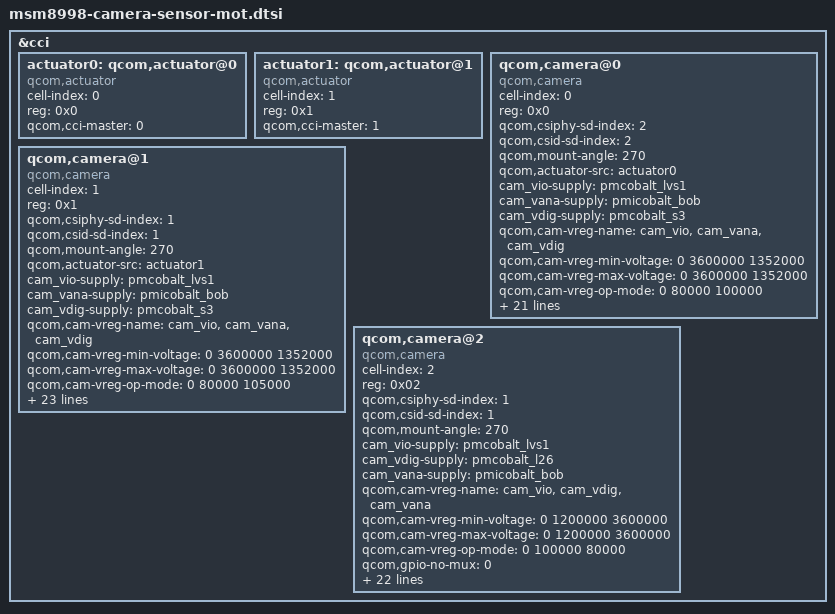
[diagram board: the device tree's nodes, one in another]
/*
 * Copyright (c) 2016, The Linux Foundation. All rights reserved.
 *
 * This program is free software; you can redistribute it and/or modify
 * it under the terms of the GNU General Public License version 2 and
 * only version 2 as published by the Free Software Foundation.
 *
 * This program is distributed in the hope that it will be useful,
 * but WITHOUT ANY WARRANTY; without even the implied warranty of
 * MERCHANTABILITY or FITNESS FOR A PARTICULAR PURPOSE.  See the
 * GNU General Public License for more details.
 */

&cci {
	/* IMX386 RGB Actuator */
	actuator0: qcom,actuator@0 {
		cell-index = <0>;
		reg = <0x0>;
		compatible = "qcom,actuator";
		qcom,cci-master = <0>;
	};

	/* IMX386 MONO Actuator */
	actuator1: qcom,actuator@1 {
		cell-index = <1>;
		reg = <0x1>;
		compatible = "qcom,actuator";
		qcom,cci-master = <1>;
	};

	/* IMX386 RGB & IMX258*/
	qcom,camera@0 {
		cell-index = <0>;
		compatible = "qcom,camera";
		reg = <0x0>;
		qcom,csiphy-sd-index = <2>;
		qcom,csid-sd-index = <2>;
		qcom,mount-angle = <270>;
		qcom,actuator-src = <&actuator0>;
		cam_vio-supply = <&pmcobalt_lvs1>;
		cam_vana-supply = <&pmicobalt_bob>;
		cam_vdig-supply = <&pmcobalt_s3>;
		qcom,cam-vreg-name = "cam_vio", "cam_vana", "cam_vdig";
		qcom,cam-vreg-min-voltage = <0 3600000 1352000>;
		qcom,cam-vreg-max-voltage = <0 3600000 1352000>;
		qcom,cam-vreg-op-mode = <0 80000 100000>;
		qcom,gpio-no-mux = <0>;
		pinctrl-names = "cam_default", "cam_suspend";
		pinctrl-0 = <&cam_sensor_mclk2_active
				 &cam_sensor_rear_active>;
		pinctrl-1 = <&cam_sensor_mclk2_suspend
				 &cam_sensor_rear_suspend>;
		gpios = <&tlmm 15 0>,
			<&tlmm 23 0>,
			<&tlmm 24 0>,
			<&tlmm 22 0>,
			<&tlmm 104 0>;
		qcom,gpio-reset = <1>;
		qcom,gpio-vdig = <2>;
		qcom,gpio-vana = <3>;
		/* gpio-standby: IMX386 toggle line between mono and rgb */
		qcom,gpio-standby = <4>;
		qcom,gpio-req-tbl-num = <0 1 2 3 4>;
		qcom,gpio-req-tbl-flags = <1 0 0 0 0>;
		qcom,gpio-req-tbl-label = "CAMIF_MCLK2",
					"CAM_RESET0",
					"CAM_VDIG",
					"CAM_VANA",
					"CAM_STANDBY";
		qcom,sensor-position = <1>;
		qcom,sensor-mode = <0>;
		qcom,cci-master = <0>;
		status = "ok";
		clocks = <&clock_mmss clk_mclk2_clk_src>,
				<&clock_mmss clk_mmss_camss_mclk2_clk>;
		clock-names = "cam_src_clk", "cam_clk";
		qcom,clock-rates = <24000000 0>;
	};

	/* IMX386 MONO and IMX258 MONO */
	qcom,camera@1 {
		cell-index = <1>;
		compatible = "qcom,camera";
		reg = <0x1>;
		qcom,csiphy-sd-index = <1>;
		qcom,csid-sd-index = <1>;
		qcom,mount-angle = <270>;
		qcom,actuator-src = <&actuator1>;
		cam_vio-supply = <&pmcobalt_lvs1>;
		cam_vana-supply = <&pmicobalt_bob>;
		cam_vdig-supply = <&pmcobalt_s3>;
		qcom,cam-vreg-name = "cam_vio", "cam_vana", "cam_vdig";
		qcom,cam-vreg-min-voltage = <0 3600000 1352000>;
		qcom,cam-vreg-max-voltage = <0 3600000 1352000>;
		qcom,cam-vreg-op-mode = <0 80000 105000>;
		qcom,gpio-no-mux = <0>;
		pinctrl-names = "cam_default", "cam_suspend";
		pinctrl-0 = <&cam_sensor_mclk2_active
				 &cam_sensor_rear_active>;
		pinctrl-1 = <&cam_sensor_mclk2_suspend
				 &cam_sensor_rear_suspend>;
		gpios = <&tlmm 15 0>,
			<&tlmm 23 0>,
			<&tlmm 24 0>,
			<&tlmm 22 0>,
			<&tlmm 128 0>,
			<&tlmm 104 0>;
		qcom,gpio-reset = <1>;
		qcom,gpio-vdig = <2>;
		qcom,gpio-vana = <3>;
		qcom,gpio-standby = <4>;
		/* gpio-custom1: IMX386 toggle line between mono and rgb */
		qcom,gpio-custom1 = <5>;
		qcom,gpio-req-tbl-num = <0 1 2 3 4 5>;
		qcom,gpio-req-tbl-flags = <1 0 0 0 0 0>;
		qcom,gpio-req-tbl-label = "CAMIF_MCLK2",
					"CAM_RESET0",
					"CAM_VDIG",
					"CAM_VANA",
					"CAM_STANDBY",
					"CAM_CUSTOM1";
		qcom,sensor-position = <1>;
		qcom,sensor-mode = <0>;
		qcom,cci-master = <1>;
		status = "ok";
		clocks = <&clock_mmss clk_mclk2_clk_src>,
				<&clock_mmss clk_mmss_camss_mclk2_clk>;
		clock-names = "cam_src_clk", "cam_clk";
		qcom,clock-rates = <24000000 0>;
	};

	/* OV5693 & OV5695 */
	qcom,camera@2 {
		cell-index = <2>;
		compatible = "qcom,camera";
		reg = <0x02>;
		qcom,csiphy-sd-index = <1>;
		qcom,csid-sd-index = <1>;
		qcom,mount-angle = <270>;
		cam_vio-supply = <&pmcobalt_lvs1>;
		cam_vdig-supply = <&pmcobalt_l26>;
		cam_vana-supply = <&pmicobalt_bob>;
		qcom,cam-vreg-name = "cam_vio", "cam_vdig", "cam_vana";
		qcom,cam-vreg-min-voltage = <0 1200000 3600000>;
		qcom,cam-vreg-max-voltage = <0 1200000 3600000>;
		qcom,cam-vreg-op-mode = <0 100000 80000>;
		qcom,gpio-no-mux = <0>;
		pinctrl-names = "cam_default", "cam_suspend";
		pinctrl-0 = <&cam_sensor_mclk1_active
			&cam_sensor_front_active>;
		pinctrl-1 = <&cam_sensor_mclk1_suspend
			&cam_sensor_front_suspend>;
		gpios = <&tlmm 14 0>,
			<&tlmm 16 0>,
			<&tlmm 104 0>,
			<&tlmm 128 0>,
			<&tlmm 24 0>,
			<&tlmm 22 0>;
		qcom,gpio-reset = <1>;
		qcom,gpio-vana = <2>;
		qcom,gpio-standby = <3>;
		qcom,gpio-vdig = <4>;
		/* Used to enable OV5695 VANA supply on daughtercard */
		qcom,gpio-custom1 = <5>;
		qcom,gpio-req-tbl-num = <0 1 2 3 4 5>;
		qcom,gpio-req-tbl-flags = <1 0 0 0 0 0>;
		qcom,gpio-req-tbl-label = "CAMIF_MCLK1",
					  "CAM_RESET1",
					  "CAM_VANA",
					  "CAM_STANDBY",
					  "CAM_VDIG",
					  "CAM_VDIG2";
		qcom,sensor-position = <1>;
		qcom,sensor-mode = <0>;
		qcom,cci-master = <0>;
		status = "ok";
		clocks = <&clock_mmss clk_mclk1_clk_src>,
			<&clock_mmss clk_mmss_camss_mclk1_clk>;
		clock-names = "cam_src_clk", "cam_clk";
		qcom,clock-rates = <24000000 0>;
	};
};
